# CY8C5888LTI_LP097 register map
File version: 0.1
CY8C58LP
Registers are 8-bit, read-write, no defined reset value unless marked. A register's access mark holds for its fields unless they carry their own. Offsets are from the block's base; lines under a group give offsets from that group; [hi:lo] are bit positions; {n}, {i} and the like mark numbered series; 'fields as' and 'values as' point back to an identical list; <NAME> marks a mode.

## Memory map
0x00000000 VDAC8_1
0x00000000 One_Sec_Timer
0x00000000 Debounce_Timer
0x00000000 UART_BT — UART

## VDAC8_1
Base 0x00000000
0x400043A8 VDAC8_PM_ACT_CFG — Active Power Mode Configuration Register 8
  [4:0] en_dac — Enable DAC block(s). Populated subsystems are counted from the LSB
0x400043B8 VDAC8_PM_STBY_CFG — Standby Power Mode Configuration Register 8
  fields as VDAC8_PM_ACT_CFG
0x4000460A VDAC8_TR
  [7:0] tr — 8 Calibration bits
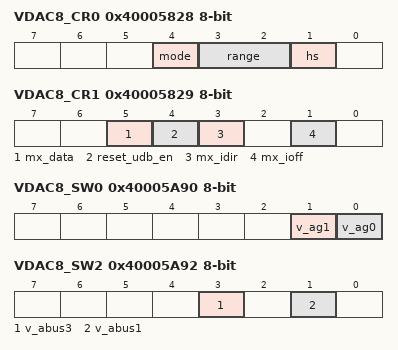
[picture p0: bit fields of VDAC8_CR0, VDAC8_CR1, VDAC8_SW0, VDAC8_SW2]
0x40005828 VDAC8_CR0 — DAC Block Control Register 0
  [4] mode ro — Mode Bit
    0=DAC_MODE_V (voltage DAC); 1=DAC_MODE_I (current DAC)
  [3:2] range — Ranges for mode=0 (VDAC) and mode=1 (IDAC)
    0=DAC_RANGE_0 (x0=0V to 4*vref (1.024V); 0 to 31.875uA); 1=DAC_RANGE_1 (x1=0V to 16*vref (4.096V); 0 to 255uA); 2=DAC_RANGE_2 (x0=0V to 4*vref (1.024V); 0 to 2.040mA); 3=DAC_RANGE_3 (x1=0V to 16*vref (4.096V); not used)
  [1] hs — High Speed Bit
    0=DAC_HS_LOWPOWER (regular (low power)); 1=DAC_HS_HIGHSPEED (high speed (higher power))
0x40005829 VDAC8_CR1 — DAC Block Control Register 1
  [5] mx_data — Select DATA source
    0=MX_DATA_REG (Select register source (DACxn_D)); 1=MX_DATA_UDB (Select UDB source)
  [4] reset_udb_en — DAC reset enable
    0=RESET_UDB_EN_DISABLE (Disable DAC Reset Source from UDB (System reset always resets)); 1=RESET_UDB_EN_ENABLE (Enable DAC Reset Source from UDB)
  [3] mx_idir — Mux selection for DAC current direction control
    0=MX_IDIR_REG (Register source idirbit selected); 1=MX_IDIR_UDB (UDB ictrl selected)
  [1] mx_ioff — Mux selection for DAC current off control
    0=MX_IOFF_REG (Register source ioffbit selected); 1=MX_IOFF_UDB (UDB ictrl selected)
0x40005A90 VDAC8_SW0 — DAC Analog Routing Register 0
  [1] v_ag1 — Connect voltage output to analog global of same side
    0=AG_NC (not connected); 1=AG_CONNECTED (Connect to Analog Global)
  [0] v_ag0 — Connect voltage output to analog global of same side
    values as v_ag1
0x40005A92 VDAC8_SW2 — DAC Analog Routing Register 2
  [3] v_abus3 — Connect voltage output to analog (local) bus of the same side
    0=ABUS_NC (not connected); 1=ABUS_CONNECTED (Connect to Analog (local) Bus)
  [1] v_abus1 — Connect voltage output to analog (local) bus of the same side
    values as v_abus3
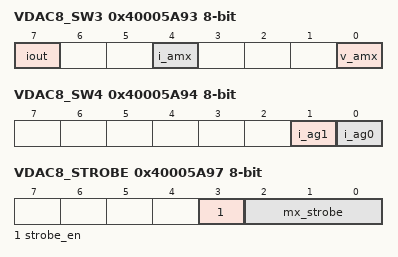
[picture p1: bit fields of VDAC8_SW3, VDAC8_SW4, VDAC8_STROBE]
0x40005A93 VDAC8_SW3 — DAC Analog Routing Register 3
  [7] iout — Connect current output to pad
    0=IOUT_NC (not connected); 1=IOUT_CONNECT (Connect to pad)
  [4] i_amx — Connect current output to Analog Mux Bus
    0=AMX_NC (not connected); 1=AMX_CONNECTED (Connect to AMUXBUS)
  [0] v_amx — Connect voltage output to Analog Mux Bus
    values as i_amx
0x40005A94 VDAC8_SW4 — DAC Analog Routing Register 4
  [1] i_ag1 — Connect current output to analog global of same side
    values as VDAC8_SW0.v_ag1
  [0] i_ag0 — Connect current output to analog global of same side
    values as VDAC8_SW0.v_ag1
0x40005A97 VDAC8_STROBE — DAC Strobe Register
  [3] strobe_en — Strobe gating control (See mx_strobe==3'h0)
    0=disable strobe; 1=enable strobe
  [2:0] mx_strobe — Strobe source selection
    0=MX_STROBE_BUSWRITE (Select bus write strobe source (Enable gater regardless of strobe_en setting)); 1=MX_STROBE_UDB_SRC (Select UDB strobe source); 2=MX_STROBE_NC_2 (NC); 3=MX_STROBE_NC_3 (NC); {v}=MX_STROBE_CLK_A{v-4}_DIG (Select clk_a{v-4}_dig) (v=4..7)
0x40005B82 VDAC8_DATA — DAC Data Register
  [7:0] data — 8 DAC Data bits

## One_Sec_Timer
Base 0x00000000
0x400043A3 One_Sec_Timer_GLOBAL_ENABLE — PM.ACT.CFG
  [3:0] en_timer — Enable timer/counters.
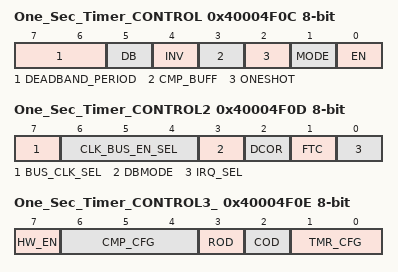
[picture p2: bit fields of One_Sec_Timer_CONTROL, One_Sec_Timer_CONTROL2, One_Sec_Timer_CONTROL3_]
0x40004F0C One_Sec_Timer_CONTROL — TMRx.CFG0
  [7:6] DEADBAND_PERIOD
  [5] DB — Deadband mode--Deadband phases phi1 and phi2 are outputted on CMP and TC output pins respectively.
    0=Timer (CMP and TC are output.); 1=Deadband (PHI1 (instead of CMP) and PHI2 (instead of TC) are output.)
  [4] INV — Invert sense of TIMEREN signal
  [3] CMP_BUFF — Buffer compare register. Compare register updates only on timer terminal count.
  [2] ONESHOT — Timer stops upon reaching stop condition defined by TMR_CFG bits. Can be restarted by asserting TIMER RESET or disabling and re-enabling block.
  [1] MODE — Mode. (0 = Timer; 1 = Comparator)
    0=Timer mode. CNT/CMP register holds timer count value.; 1=Comparator mode. CNT/CMP register holds comparator threshold value.
  [0] EN — Enables timer/comparator.
0x40004F0D One_Sec_Timer_CONTROL2 — TMRx.CFG1
  [7] BUS_CLK_SEL — Bus Clock selection.
  [6:4] CLK_BUS_EN_SEL — Digital Global Clock selection.
  [3] DBMODE — Deadband mode (asynchronous/synchronous). CMP output pin is also affected when not in deadband mode (CFG0.DEADBAND).
  [2] DCOR — Disable Clear on Read (DCOR) of Status Register SR0.
  [1] FTC — First Terminal Count (FTC). Setting this bit forces a single pulse on the TC pin when first enabled.
    0=Disable_FTC (Disable the single cycle pulse, which signifies the timer is starting.); 1=Enable_FTC (Enable the single cycle pulse, which signifies the timer is starting.)
  [0] IRQ_SEL — Irq selection. (0 = raw interrupts; 1 = status register interrupts)
0x40004F0E One_Sec_Timer_CONTROL3_ — TMRx.CFG2
  [7] HW_EN — When set Timer Enable controls counting.
  [6:4] CMP_CFG — Comparator configurations
    0=Equal (Compare Equal); 1=Less_than (Compare Less Than); 2=Less_than_or_equal (Compare Less Than or Equal .); 3=Greater (Compare Greater Than .); 4=Greater_than_or_equal (Compare Greater Than or Equal)
  [3] ROD — Reset On Disable (ROD). Resets internal state of output logic
  [2] COD — Clear On Disable (COD). Clears or gates outputs to zero.
  [1:0] TMR_CFG — Timer configuration (MODE = 0): 000 = Continuous; 001 = Pulsewidth; 010 = Period; 011 = Stop on IRQ
    0=Continuous (Timer runs while EN bit of CFG0 register is set to '1'.); 1=Pulsewidth (Timer runs from positive to negative edge of TIMEREN.); 2=Period (Timer runs from positive to positive edge of TIMEREN.); 3=Irq (Timer runs until IRQ.)
0x40004F10 One_Sec_Timer_PERIOD 16-bit — TMRx.PER0 - Assigned Period
0x40004F12 One_Sec_Timer_COUNTER 16-bit — TMRx.CNT_CMP0 - Current Down Counter Value

## Debounce_Timer
Base 0x00000000
0x400043A3 Debounce_Timer_GLOBAL_ENABLE — PM.ACT.CFG
  [3:0] en_timer — Enable timer/counters.
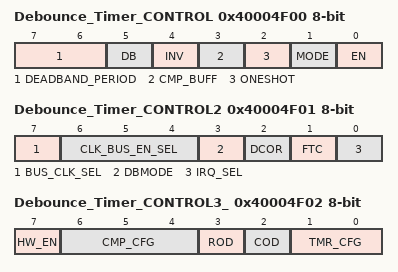
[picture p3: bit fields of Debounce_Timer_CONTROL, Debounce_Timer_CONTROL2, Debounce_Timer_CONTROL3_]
0x40004F00 Debounce_Timer_CONTROL — TMRx.CFG0
  fields as One_Sec_Timer.One_Sec_Timer_CONTROL
0x40004F01 Debounce_Timer_CONTROL2 — TMRx.CFG1
  fields as One_Sec_Timer.One_Sec_Timer_CONTROL2
0x40004F02 Debounce_Timer_CONTROL3_ — TMRx.CFG2
  fields as One_Sec_Timer.One_Sec_Timer_CONTROL3_
0x40004F04 Debounce_Timer_PERIOD — TMRx.PER0 - Assigned Period
0x40004F06 Debounce_Timer_COUNTER — TMRx.CNT_CMP0 - Current Down Counter Value

## UART_BT — UART
Base 0x00000000
0x40006423 RX_UART_BT_RX_ADDRESS1 — RX Address1 Register
0x40006433 RX_UART_BT_RX_ADDRESS2 — RX Address2 Register
0x40006443 RX_UART_BT_RX_DATA — RX Data Register
0x40006444 TX_UART_BT_TX_DATA — TX Data Register
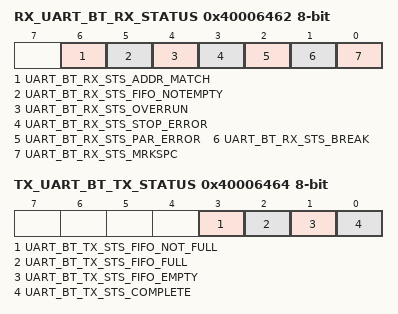
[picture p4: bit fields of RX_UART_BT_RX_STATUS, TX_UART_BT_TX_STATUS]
0x40006462 RX_UART_BT_RX_STATUS — RX status register
  [6] UART_BT_RX_STS_ADDR_MATCH ro, [5] UART_BT_RX_STS_FIFO_NOTEMPTY ro, [4] UART_BT_RX_STS_OVERRUN ro, [3] UART_BT_RX_STS_STOP_ERROR ro, [2] UART_BT_RX_STS_PAR_ERROR ro, [1] UART_BT_RX_STS_BREAK ro, [0] UART_BT_RX_STS_MRKSPC ro
0x40006464 TX_UART_BT_TX_STATUS — TX status register
  [3] UART_BT_TX_STS_FIFO_NOT_FULL ro, [2] UART_BT_TX_STS_FIFO_FULL ro, [1] UART_BT_TX_STS_FIFO_EMPTY ro, [0] UART_BT_TX_STS_COMPLETE ro
